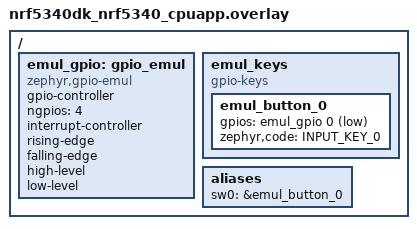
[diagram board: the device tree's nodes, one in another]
/* On the DK only sw0 moves; led0 stays on the real LED1, so each test_btn
 * press blinks a physical LED. This file replaces app.overlay for this board
 * rather than adding to it, so the emulated controller is declared again here.
 */
#include <zephyr/dt-bindings/gpio/gpio.h>
#include <zephyr/dt-bindings/input/input-event-codes.h>

/ {
    emul_gpio: gpio_emul {
        compatible = "zephyr,gpio-emul";
        status = "okay";
        gpio-controller;
        #gpio-cells = <2>;
        ngpios = <4>;
        interrupt-controller;
        #interrupt-cells = <2>;
        rising-edge;
        falling-edge;
        high-level;
        low-level;
    };

    emul_keys {
        compatible = "gpio-keys";
        emul_button_0: emul_button_0 {
            gpios = <&emul_gpio 0 GPIO_ACTIVE_LOW>;
            zephyr,code = <INPUT_KEY_0>;
        };
    };

    /* sw0 moves because pytest cannot press the physical button, which is
     * left unbound in this image. */
    aliases {
        sw0 = &emul_button_0;
    };
};
